VERSION ""

NS_ :

BS_:

BU_:

BO_ 2566877209 ThermoHV_1_Control: 8 Vector__XXX
 SG_ D_HVH1ModeRequest : 0|4@1+ (1,0) [0|15] "" Vector__XXX
 SG_ D_HVH1DiagnosticRequests : 32|8@1+ (1,0) [0|255] "" Vector__XXX

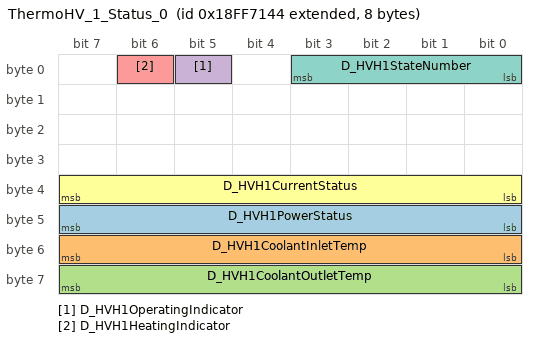
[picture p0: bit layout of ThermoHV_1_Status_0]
BO_ 2566877508 ThermoHV_1_Status_0: 8 Vector__XXX
 SG_ D_HVH1PowerStatus : 40|8@1+ (0.1,0) [0|25.5] "kW" Vector__XXX
 SG_ D_HVH1CoolantInletTemp : 48|8@1+ (1,-40) [-40|149] "�C" Vector__XXX
 SG_ D_HVH1CoolantOutletTemp : 56|8@1+ (1,-40) [-40|149] "�C" Vector__XXX
 SG_ D_HVH1OperatingIndicator : 5|1@1+ (1,0) [0|1] "" Vector__XXX
 SG_ D_HVH1HeatingIndicator : 6|1@1+ (1,0) [0|1] "" Vector__XXX
 SG_ D_HVH1CurrentStatus : 32|8@1+ (0.1,0) [0|25.5] "A" Vector__XXX
 SG_ D_HVH1StateNumber : 0|4@1+ (1,0) [0|15] "" Vector__XXX

CM_ SG_ 2566877209 D_HVH1WaterTempSetpoint "SAEtp01";
CM_ SG_ 2566877209 D_HVH1PowerLimitation "SAEpw07";
CM_ SG_ 2566877209 D_HVH1ModeRequest "SAEbs04";
CM_ SG_ 2566877209 D_HVH1DiagnosticRequests "SAEbs04";
CM_ SG_ 2566877508 D_HVH1PowerStatus "SAEpw07";
CM_ SG_ 2566877508 D_HVH1CoolantInletTemp "SAEtp01";
CM_ SG_ 2566877508 D_HVH1CoolantOutletTemp "SAEtp01";
CM_ SG_ 2566877508 D_HVH1CurrentStatus "SAEec03";
CM_ SG_ 2566877508 D_HVH1SetpointStatus "SAEtp01";
CM_ SG_ 2566877508 D_HVH1HVVoltageOutStatus "SAEev02";

BA_DEF_  "BusType" STRING ;
BA_DEF_ BO_  "GenMsgCycleTime" INT 0 65535;
BA_DEF_ SG_  "GenSigStartValue" FLOAT -3.4E+038 3.4E+038;
BA_DEF_DEF_  "BusType" "CAN";
BA_DEF_DEF_  "GenMsgCycleTime" 0;
BA_DEF_DEF_  "GenSigStartValue" 0;

BA_ "GenMsgCycleTime" BO_ 2566877209 1000;
BA_ "GenMsgCycleTime" BO_ 2566877508 100;
BA_ "GenSigStartValue" SG_ 2566877508 D_HVH1SetpointStatus 40;

VAL_ 2566879889 ThermoHV_4_Debug_0_Mux 9 "HVH1_MUX_CurrLimits" ;
VAL_ 2566879888 ThermoHV_3_Debug_0_Mux 9 "HVH1_MUX_CurrLimits" ;
VAL_ 2566879813 ThermoHV_2_Debug_0_Mux 9 "HVH1_MUX_CurrLimits" ;
VAL_ 2566879812 ThermoHV_1_Debug_0_Mux 9 "HVH1_MUX_CurrLimits" ;
VAL_ 2566877209 D_HVH1ModeRequest 0 "De-activate" 3 "Normal mode" 4 "Ext_CoolantPump_RQ" ;
VAL_ 2566877209 D_HVH1DiagnosticRequests 20 "Discharge" 19 "Send_MUX_All" 0 "Off" 2 "ExtResetHeaterLock" 3 "ExtResetFaultLock" ;
VAL_ 2566877508 D_HVH1CoolantInletTemp 255 "Not Available" 254 "Error (out of range)" ;
VAL_ 2566877508 D_HVH1CoolantOutletTemp 255 "Not Available" 254 "Error (out of range)" ;
VAL_ 2566877508 D_HVH1OperatingIndicator 1 "ON" 0 "OFF" ;
VAL_ 2566877508 D_HVH1HeatingIndicator 1 "ON" 0 "OFF" ;
VAL_ 2566877508 D_HVH1StateNumber 12 "Pre-Run Extended" 0 "None" 1 "Ready" 2 "Pre-Run" 7 "Heating" 9 "Cool Down" 11 "CPRC" ;
VAL_ 2566877508 D_HVH1PumpRequest 1 "ON" 0 "OFF" ;
